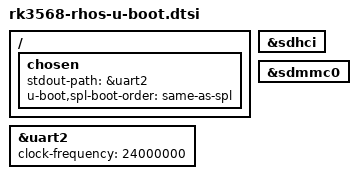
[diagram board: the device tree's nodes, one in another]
// SPDX-License-Identifier: GPL-2.0+
/*
 * Copyright (c) 2024 Radioavionica Corp
 *   190005, Russia, Saint-Petersburg, Troitsky pr. 4, lit "B"
 * Copyright (c) 2024 Alex A. Mihaylov <minimumlaw@rambler.ru>
 */

#include "rk356x-u-boot.dtsi"

/ {
	chosen {
		stdout-path = &uart2;
		u-boot,spl-boot-order = "same-as-spl", &sdmmc0, &sdhci;
	};
};

&sdhci {
	u-boot,dm-spl;
	status = "okay";
};

&sdmmc0 {
	u-boot,dm-spl;
	status = "okay";
};

&uart2 {
	clock-frequency = <24000000>;
	u-boot,dm-spl;
	status = "okay";
};
